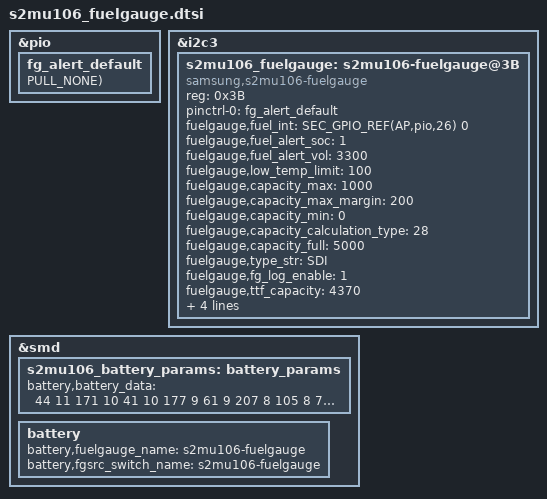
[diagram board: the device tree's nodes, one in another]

&pio {
	fg_alert_default: fg_alert_default {
		GPIO_CONFIG_PUD(AP,pio,26, FUNC_INPUT_WAKEUP, PULL_NONE);
	};
};

&i2c3 {
	status = "okay";

	s2mu106_fuelgauge: s2mu106-fuelgauge@3B {
		compatible = "samsung,s2mu106-fuelgauge";
		reg = <0x3B>;
		pinctrl-names = "default";
		pinctrl-0 = <&fg_alert_default>;
		fuelgauge,fuel_int = <SEC_GPIO_REF(AP,pio,26) 0>;
		fuelgauge,fuel_alert_soc = <1>;
		fuelgauge,fuel_alert_vol = <3300>;
		fuelgauge,low_temp_limit = <100>;
		fuelgauge,capacity_max = <1000>;
		fuelgauge,capacity_max_margin = <200>;
		fuelgauge,capacity_min = <0>;
		fuelgauge,capacity_calculation_type = <28>;
		fuelgauge,capacity_full = <4370>;
		fuelgauge,type_str = "SDI";
		fuelgauge,fg_log_enable = <1>;

		fuelgauge,ttf_capacity = <4370>;
		fuelgauge,cv_data = <
			2488	829	1809
			2409	832	1796
			2327	837	1769
			2272	840	1743
			2182	846	1721
			2104	850	1690
			2038	854	1670
			1950	859	1640
			1904	861	1622
			1838	865	1594
			1797	867	1576
			1749	870	1560
			1703	873	1531
			1683	873	1525
			1667	875	1515
			1660	875	1512
			1653	876	1509
			1615	878	1502
			1580	880	1483
			1553	881	1463
			1544	882	1458
			1520	883	1451
			1477	886	1424
			1431	888	1409
			1396	891	1383
			1347	894	1361
			1299	896	1332
			1267	898	1315
			1231	902	1288
			1202	904	1263
			1148	906	1243
			1109	909	1213
			1067	911	1185
			1031	914	1156
			1013	915	1140
			975	917	1111
			961	919	1084
			921	921	1064
			892	923	1038
			887	923	1019
			863	925	1004
			833	927	976
			808	929	946
			787	930	918
			780	931	904
			764	932	895
			744	934	864
			730	935	846
			715	936	828
			693	937	800
			681	938	783
			666	940	752
			651	941	735
			640	942	712
			628	945	697
			622	946	679
			618	947	664
			600	950	646
			596	951	627
			589	953	614
			584	953	601
			576	956	572
			577	957	553
			562	958	535
			511	968	506
			505	969	487
			493	971	464
			492	972	435
			484	973	417
			480	975	398
			474	976	380
			470	977	364
			462	977	355
			456	978	336
			452	979	329
			446	981	303
			437	982	282
			429	984	255
			423	985	242
			422	986	229
			414	987	211
			411	988	199
			405	989	191
			397	990	171
			391	991	140
			387	992	126
			384	993	107
			372	995	84
			364	997	54
			356	998	26
			356	998	13
			0	1000	0
			>;
	};
};

&smd {
	s2mu106_battery_params: battery_params {
		battery,battery_data =
			<
			/***** battery data for 4.35 *****/
			/* battery,battery_table3 */
			5 11 139 10 16 10 158 9 48 9
			196 8 118 8 227 7 173 7 65 7
			236 6 182 6 139 6 104 6 76 6
			41 6 0 6 218 5 156 5 131 5
			156 4 133 1 106 8 0 8 150 7
			43 7 193 6 87 6 236 5 130 5
			24 5 174 4 67 4 217 3 111 3
			4 3 154 2 48 2 198 1 91 1
			241 0 135 0 28 0 214 15

			/* battery,battery_table4 */
			10 10 10 10 26 26 25 24 24 24
			23 23 24 24 25 26 27 28 29 31
			36 86

			/* battery,batcap */
			0x48 0x44 0xAC 0x0D /* [0x0E] [0x0F] [0x10] [0x11] */
			/* battery,accum */ 
			0x00 0x08 /* [0x44] [0x45] */

			/* battery,soc_arr_val */
			10519 10000 9480 8961 8442 7923 7404 6885 6366 5847
			5328 4809 4290 3771 3252 2733 2214 1695 1176 657
			138 (-204)

			/* battery,ocv_arr_val */
			43776 43177 42578 42019 41484 40959 40574 39857 39595 39069
			38654 38389 38177 38009 37872 37701 37498 37312 37010 36890
			35763 31899

			/* battery,tunning */
			0x00

			/***** battery data for 4.33 *****/
			/* battery,battery_table3 */
			5	11	139	10	16	10	158	9	48	9
			196	8	118	8	227	7	173	7	65	7
			236	6	182	6	139	6	104	6	76	6
			41	6	0	6	218	5	156	5	131	5
			156	4	133	1	159	8	50	8	197	7
			88	7	235	6	126	6	17	6	165	5
			56	5	203	4	94	4	241	3	132	3
			23	3	170	2	61	2	209	1	100	1
			247	0	138	0	29	0	213	15

			/* battery,battery_table4 */
			26	26	26	26	26	26	25	24	24	24
			23	23	24	24	25	26	27	28	29	31
			36	36

			/* battery,batcap */
			0x68 0x42 0x9A 0x10 /* [0x0E] [0x0F] [0x10] [0x11] */
			/* battery,accum */
			0x00 0x08 /* [0x44] [0x45] */

			/* battery,soc_arr_val */
			10775	10243	9711	9180	8648	8116	7585	7053	6521	5990
			5458	4926	4395	3863	3331	2800	2268	1736	1205	673
			141	(-209)

			/* battery,ocv_arr_val */
			43776	43177	42578	42019	41484	40959	40574	39857	39595	39069
			38654	38389	38177	38009	37872	37701	37498	37312	37010	36890
			35763	31899

			/* battery,tunning */
			0x00

			/***** battery data for 4.31 *****/
			/* battery,battery_table3 */
			5	11	139	10	16	10	158	9	48	9
			196	8	118	8	227	7	173	7	65	7
			236	6	182	6	139	6	104	6	76	6
			41	6	0	6	218	5	156	5	131	5
			156	4	133	1	197	8	86	8	231	7
			121	7	10	7	155	6	44	6	190	5
			79	5	224	4	113	4	2	4	148	3
			37	3	182	2	71	2	217	1	106	1
			251	0	140	0	30	0	212	15

			/* battery,battery_table4 */
			26	26	26	26	26	26	25	24	24	24
			23	23	24	24	25	26	27	28	29	31
			36	36

			/* battery,batcap */
			0x50 0x41 0x54 0x10 /* [0x0E] [0x0F] [0x10] [0x11] */
			/* battery,accum */
			0x00 0x08 /* [0x44] [0x45] */

			/* battery,soc_arr_val */
			10961	10420	9880	9339	8798	8257	7716	7175	6634	6093
			5553	5012	4471	3930	3389	2848	2307	1766	1225	685
			144	(-213)

			/* battery,ocv_arr_val */
			43776	43177	42578	42019	41484	40959	40574	39857	39595	39069
			38654	38389	38177	38009	37872	37701	37498	37312	37010	36890
			35763	31899

			/* battery,tunning */
			0x00

			/***** battery data for 4.29 *****/
			/* battery,battery_table3 */
			5	11	139	10	16	10	158	9	48	9
			196	8	118	8	227	7	173	7	65	7
			236	6	182	6	139	6	104	6	76	6
			41	6	0	6	218	5	156	5	131	5
			156	4	133	1	237	8	124	8	11	8
			154	7	42	7	185	6	72	6	215	5
			103	5	246	4	133	4	21	4	164	3
			51	3	194	2	82	2	225	1	112	1
			255	0	143	0	30	0	212	15

			/* battery,battery_table4 */
			26	26	26	26	26	26	25	24	24	24
			23	23	24	24	25	26	27	28	29	31
			36	36

			/* battery,batcap */
			0x38 0x40 0x0E 0x10 /* [0x0E] [0x0F] [0x10] [0x11] */
			/* battery,accum */
			0x00 0x08 /* [0x44] [0x45] */

			/* battery,soc_arr_val */
			11155	10604	10054	9503	8953	8403	7852	7302	6751	6201
			5650	5100	4550	3999	3449	2898	2348	1798	1247	697
			146	(-217)

			/* battery,ocv_arr_val */
			43776	43177	42578	42019	41484	40959	40574	39857	39595	39069
			38654	38389	38177	38009	37872	37701	37498	37312	37010	36890
			35763	31899

			/* battery,tunning */
			0x00

			/***** battery data for 4.24 *****/
			/* battery,battery_table3 */
			5	11	139	10	16	10	158	9	48	9
			196	8	118	8	227	7	173	7	65	7
			236	6	182	6	139	6	104	6	76	6
			41	6	0	6	218	5	156	5	131	5
			156	4	133	1	77	9	215	8	98	8
			236	7	119	7	1	7	140	6	22	6
			161	5	43	5	182	4	64	4	203	3
			86	3	224	2	107	2	245	1	128	1
			10	1	149	0	31	0	210	15

			/* battery,battery_table4 */
			26	26	26	26	26	26	25	24	24	24
			23	23	24	24	25	26	27	28	29	31
			36	36

			/* battery,batcap */
			0x08 0x3E 0x82 0x0F /* [0x0E] [0x0F] [0x10] [0x11] */
			/* battery,accum */
			0x00 0x08 /* [0x44] [0x45] */

			/* battery,soc_arr_val */
			11623	11050	10476	9903	9329	8756	8182	7608	7035	6461
			5888	5314	4741	4167	3594	3020	2447	1873	1300	726
			152	(-226)

			/* battery,ocv_arr_val */
			43776	43177	42578	42019	41484	40959	40574	39857	39595	39069
			38654	38389	38177	38009	37872	37701	37498	37312	37010	36890
			35763	31899

			/* battery,tunning */
			0x00
			>;
	};
};

&smd {
		battery {
			battery,fuelgauge_name = "s2mu106-fuelgauge";
			battery,fgsrc_switch_name = "s2mu106-fuelgauge"; /* Fuelgauge voltage source */
		};
};

/* /home/dpi/qb5_8814/workspace/P4_1716/android/kernel/kmodule/battery/fuelgauge/s2mu106_fuelgauge/s2mu106_fuelgauge.a31.dtsi */

&s2mu106_fuelgauge {
		fuelgauge,low_voltage_limit_lowtemp = <3100>;
		fuelgauge,i_socr_coeff = <84>;
		fuelgauge,capacity_full = <5000>;
};

&s2mu106_battery_params {
		battery,battery_data =
			<
			/***** battery data for 4.38 *****/
			/* battery,battery_table3 */
			44 11 171 10 41 10 177 9 61 9
			207 8 105 8 7 8 183 7 93 7
			243 6 184 6 139 6 104 6 77 6
			50 6 11 6 226 5 159 5 128 5
			149 4 116 1 106 8 0 8 150 7
			43 7 193 6 86 6 236 5 129 5
			23 5 173 4 66 4 216 3 109 3
			3 3 153 2 46 2 196 1 89 1
			239 0 132 0 26 0 220 15

			/* battery,battery_table4 */
			10 10 10 10 55 54 54 54 53 53
			54 54 55 55 56 57 57 58 60 66
			77 154

			/* battery,batcap */
			0x10 0x49 0x44 0x12 /* [0x0E] [0x0F] [0x10] [0x11] */
			/* battery,accum */
			0x00 0x08 /* [0x44] [0x45] */

			/* battery,soc_arr_val */
			10520 10000 9480 8961 8441 7921 7402 6882 6363 5843
			5323 4804 4284 3764 3245 2725 2206 1686 1166 647
			127 (-176)

			/* battery,ocv_arr_val */
			43964 43333 42702 42115 41549 41009 40513 40036 39643 39203
			38684 38396 38180 38009 37874 37746 37553 37352 37027 36876
			35729 31817

			/* battery,tuning */
			0x00

			/***** battery data for 4.36 *****/
			/* battery,battery_table3 */
			44 11 171 10 41 10 177 9 61 9
			207 8 105 8 7 8 183 7 93 7
			243 6 184 6 139 6 104 6 77 6
			50 6 11 6 226 5 159 5 128 5
			149 4 116 1 134 8 27 8 175 7
			68 7 216 6 109 6 1 6 150 5
			43 5 191 4 84 4 232 3 125 3
			17 3 166 2 59 2 207 1 100 1
			248 0 141 0 33 0 227 15

			/* battery,battery_table4 */
			10 10 10 10 55 54 54 54 53 53
			54 54 55 55 56 57 57 58 60 66
			77 154

			/* battery,batcap */
			0x60 0x48 0xDB 0x0A  /* [0x0E] [0x0F] [0x10] [0x11] */
			/* battery,accum */
			0x00 0x8 /* [0x44] [0x45] */

			/* battery,soc_arr_val */
			10654 10130 9605 9080 8556 8031 7507 6982 6458 5933
			5409 4884 4360 3835 3310 2786 2261 1737 1212 688
			163 (-143)
			/* battery,ocv_arr_val */
			43964 43333 42702 42115 41549 41009 40513 40036 39643 39203
			38684 38396 38180 38009 37874 37746 37553 37352 37027 36876
			35729 31817

			/* battery,tuning */
			0x00

			/***** battery data for 4.34 *****/
			/* battery,battery_table3 */
			44 11 171 10 41 10 177 9 61 9
			207 8 105 8 7 8 183 7 93 7
			243 6 184 6 139 6 104 6 77 6
			50 6 11 6 226 5 159 5 128 5
			149 4 116 1 172 8 63 8 210 7
			100 7 247 6 138 6 28 6 175 5
			66 5 212 4 103 4 250 3 141 3
			31 3 178 2 69 2 215 1 106 1
			253 0 143 0 34 0 226 15

			/* battery,battery_table4 */
			10 10 10 10 55 54 54 54 53 53
			54 54 55 55 56 57 57 58 60 66
			77 154

			/* battery,batcap */
			0x20 0x47 0xAB 0x0A /* [0x0E] [0x0F] [0x10] [0x11] */
			/* battery,accum */
			0x00 0x8 /* [0x44] [0x45] */

			/* battery,soc_arr_val */
			10841 10308 9774 9240 8706 8173 7639 7105 6571 6038
			5504 4970 4436 3902 3369 2835 2301 1767 1234 700
			166 (-145)
			/* battery,ocv_arr_val */
			43964 43333 42702 42115 41549 41009 40513 40036 39643 39203
			38684 38396 38180 38009 37874 37746 37553 37352 37027 36876
			35729 31817

			/* battery,tuning */
			0x00

			/***** battery data for 4.32 *****/
			/* battery,battery_table3 */
			44 11 171 10 41 10 177 9 61 9
			207 8 105 8 7 8 183 7 93 7
			243 6 184 6 139 6 104 6 77 6
			50 6 11 6 226 5 159 5 128 5
			149 4 116 1 212 8 101 8 246 7
			134 7 23 7 168 6 56 6 201 5
			90 5 235 4 123 4 12 4 157 3
			46 3 190 2 79 2 224 1 112 1
			1 1 146 0 35 0 226 15

			/* battery,battery_table4 */
			10 10 10 10 55 54 54 54 53 53
			54 54 55 55 56 57 57 58 60 66
			77 154

			/* battery,batcap */
			0xE0 0x45 0x7B 0x0A /* [0x0E] [0x0F] [0x10] [0x11] */
			/* battery,accum */
			0x00 0x8 /* [0x44] [0x45] */

			/* battery,soc_arr_val */
			11035 10492 9949 9405 8862 8319 7776 7232 6689 6146
			5602 5059 4516 3972 3429 2886 2342 1799 1256 712
			169 (-148)
			/* battery,ocv_arr_val */
			43964 43333 42702 42115 41549 41009 40513 40036 39643 39203
			38684 38396 38180 38009 37874 37746 37553 37352 37027 36876
			35729 31817

			/* battery,tuning */
			0x00

			/***** battery data for 4.27 *****/
			/* battery,battery_table3 */
			44 11 171 10 41 10 177 9 61 9
			207 8 105 8 7 8 183 7 93 7
			243 6 184 6 139 6 104 6 77 6
			50 6 11 6 226 5 159 5 128 5
			149 4 116 1 62 9 201 8 85 8
			224 7 108 7 247 6 131 6 15 6
			154 5 38 5 177 4 61 4 200 3
			84 3 223 2 107 2 246 1 130 1
			13 1 153 0 36 0 224 15

			/* battery,battery_table4 */
			10 10 10 10 55 54 54 54 53 53
			54 54 55 55 56 57 57 58 60 66
			77 154

			/* battery,batcap */
			0xC0 0x42 0x03 0x0A /* [0x0E] [0x0F] [0x10] [0x11] */
			/* battery,accum */
			0x00 0x8 /* [0x44] [0x45] */

			/* battery,soc_arr_val */
			11552 10984 10415 9846 9277 8708 8140 7571 7002 6433
			5865 5296 4727 4158 3590 3021 2452 1883 1314 746
			177 (-155)
			/* battery,ocv_arr_val */
			43964 43333 42702 42115 41549 41009 40513 40036 39643 39203
			38684 38396 38180 38009 37874 37746 37553 37352 37027 36876
			35729 31817

			/* battery,tuning */
			0x00
			>;
};
